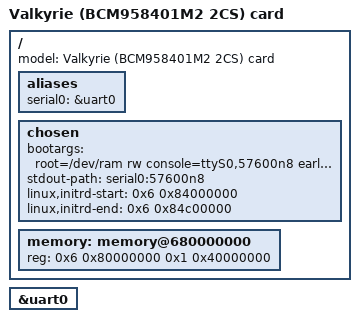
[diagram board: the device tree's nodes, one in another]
// SPDX-License-Identifier: (GPL-2.0 or BSD-3-Clause)
/*
 *  Copyright(c) 2019 Broadcom
 */

/dts-v1/;

/*
 * Reserve BL31 image area. In absence of A72 ROM,
 * Linux reboot enters at stand-alone BL31.
 */
/memreserve/ 0x682000000 0x00100000;

#include "valkyrie.dtsi"

/ {
	model = "Valkyrie (BCM958401M2 2CS) card";

	aliases {
		serial0 = &uart0;
	};

	chosen {
		bootargs = "root=/dev/ram rw console=ttyS0,57600n8 \
			   earlycon=uart8250,mmio32,0x48100000 maxcpus=1";

		stdout-path = "serial0:57600n8";
		linux,initrd-start = <0x6 0x84000000>;
		linux,initrd-end = <0x6 0x84c00000>;
	};

	memory: memory@680000000 {
		device_type = "memory";
		reg = <0x6 0x80000000 0x1 0x40000000>;
	};

};

&uart0 {
	status = "okay";
};
